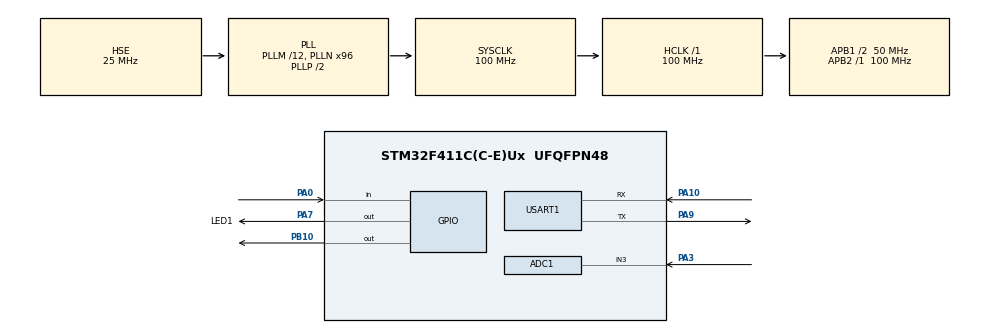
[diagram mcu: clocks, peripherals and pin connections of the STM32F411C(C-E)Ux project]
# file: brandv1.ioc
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ADC1.Channel-0\#ChannelRegularConversion=ADC_CHANNEL_3
ADC1.NbrOfConversionFlag=1
ADC1.Rank-0\#ChannelRegularConversion=1
ADC1.SamplingTime-0\#ChannelRegularConversion=ADC_SAMPLETIME_3CYCLES
ADC1.master=1
Mcu.Family=STM32F4
Mcu.Name=STM32F411C(C-E)Ux
Mcu.Package=UFQFPN48
NVIC.PriorityGroup=NVIC_PRIORITYGROUP_2
NVIC.TIM1_BRK_TIM9_IRQn=true\:2\:0\:true\:false\:true\:true\:true\:true
NVIC.USART1_IRQn=true\:2\:2\:true\:false\:true\:true\:true\:true
PA0-WKUP.GPIO_PuPd=GPIO_NOPULL
PA0-WKUP.Signal=GPIO_Input
PA10.Mode=Asynchronous
PA10.Signal=USART1_RX
PA13.Mode=Serial_Wire
PA13.Signal=SYS_JTMS-SWDIO
PA14.Mode=Serial_Wire
PA14.Signal=SYS_JTCK-SWCLK
PA3.Signal=ADCx_IN3
PA7.GPIO_Label=LED1
PA7.PinState=GPIO_PIN_SET
PA7.Signal=GPIO_Output
PA9.Mode=Asynchronous
PA9.Signal=USART1_TX
PB10.Signal=GPIO_Output
PC14-OSC32_IN.Mode=LSE-External-Oscillator
PC14-OSC32_IN.Signal=RCC_OSC32_IN
PC15-OSC32_OUT.Mode=LSE-External-Oscillator
PC15-OSC32_OUT.Signal=RCC_OSC32_OUT
PH0\ -\ OSC_IN.Mode=HSE-External-Oscillator
PH0\ -\ OSC_IN.Signal=RCC_OSC_IN
PH1\ -\ OSC_OUT.Mode=HSE-External-Oscillator
PH1\ -\ OSC_OUT.Signal=RCC_OSC_OUT
ProjectManager.HeapSize=0x200
ProjectManager.StackSize=0x400
ProjectManager.TargetToolchain=MDK-ARM V5.32
RCC.48MHZClocksFreq_Value=50000000
RCC.AHBFreq_Value=100000000
RCC.APB1CLKDivider=RCC_HCLK_DIV2
RCC.APB1Freq_Value=50000000
RCC.APB1TimFreq_Value=100000000
RCC.APB2Freq_Value=100000000
RCC.APB2TimFreq_Value=100000000
RCC.CortexFreq_Value=100000000
RCC.HCLKFreq_Value=100000000
RCC.HSE_VALUE=25000000
RCC.HSI_VALUE=16000000
RCC.PLLM=12
RCC.PLLN=96
RCC.PLLSourceVirtual=RCC_PLLSOURCE_HSE
RCC.SYSCLKFreq_VALUE=100000000
RCC.SYSCLKSource=RCC_SYSCLKSOURCE_PLLCLK
RCC.VCOOutputFreq_Value=200000000
SH.ADCx_IN3.0=ADC1_IN3,IN3
TIM11.AutoReloadPreload=TIM_AUTORELOAD_PRELOAD_ENABLE
TIM11.Prescaler=1000
TIM9.Period=1000-1
TIM9.Prescaler=100-1
USART1.VirtualMode=VM_ASYNC
VP_TIM11_VS_ClockSourceINT.Mode=Enable_Timer
VP_TIM11_VS_OPM.Mode=OPM_bit
VP_TIM9_VS_ClockSourceINT.Mode=Internal
board=custom

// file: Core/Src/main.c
/* USER CODE BEGIN Header */
/**
  ******************************************************************************
  * @file           : main.c
  * @brief          : Main program body
  ******************************************************************************
  * @attention
  *
  * Copyright (c) 2025 STMicroelectronics.
  * All rights reserved.
  *
  * This software is licensed under terms that can be found in the LICENSE file
  * in the root directory of this software component.
  * If no LICENSE file comes with this software, it is provided AS-IS.
  *
  ******************************************************************************
  */
/* USER CODE END Header */
#include "main.h"
#include "adc.h"
#include "tim.h"
#include "usart.h"
#include "gpio.h"

void SystemClock_Config(void);

int main(void)
{

  /* MCU Configuration--------------------------------------------------------*/

  /* Reset of all peripherals, Initializes the Flash interface and the Systick. */
  HAL_Init();

  /* Configure the system clock */
  SystemClock_Config();

  /* Initialize all configured peripherals */
  MX_GPIO_Init();
  MX_USART1_UART_Init();
  MX_TIM9_Init();
  MX_TIM11_Init();
  MX_ADC1_Init();
  /* USER CODE BEGIN 2 */

  UART_SendString("Enter\r\n");

  /* USER CODE END 2 */

  /* Infinite loop */
  /* USER CODE BEGIN WHILE */
  while (1)
  {

 Key_Event_t event = Get_Key_Event(); // 获取按键事件

    if (event != KEY_EVENT_NONE) // 如果有新事件发生
    {
        switch (event)
        {
            case KEY_EVENT_UP_PRESS:    printf("摇杆: 上\r\n"); break;
            case KEY_EVENT_DOWN_PRESS:  printf("摇杆: 下\r\n"); break;
            case KEY_EVENT_LEFT_PRESS:  printf("摇杆: 左\r\n"); break;
            case KEY_EVENT_RIGHT_PRESS: printf("摇杆: 右\r\n"); break;

            case KEY_EVENT_OK_CLICK:    printf("OK键: 单击\r\n"); break;
            case KEY_EVENT_OK_DOUBLE:   printf("OK键: 双击\r\n"); break;
            case KEY_EVENT_OK_LONG:     printf("OK键: 长按\r\n"); break;

            default: break;
        }
    }
    /* USER CODE END WHILE */

  }
}

void SystemClock_Config(void)
{
  RCC_OscInitTypeDef RCC_OscInitStruct = {0};
  RCC_ClkInitTypeDef RCC_ClkInitStruct = {0};

  /** Configure the main internal regulator output voltage
  */
  __HAL_RCC_PWR_CLK_ENABLE();
  __HAL_PWR_VOLTAGESCALING_CONFIG(PWR_REGULATOR_VOLTAGE_SCALE1);

  /** Initializes the RCC Oscillators according to the specified parameters
  * in the RCC_OscInitTypeDef structure.
  */
  RCC_OscInitStruct.OscillatorType = RCC_OSCILLATORTYPE_HSE;
  RCC_OscInitStruct.HSEState = RCC_HSE_ON;
  RCC_OscInitStruct.PLL.PLLState = RCC_PLL_ON;
  RCC_OscInitStruct.PLL.PLLSource = RCC_PLLSOURCE_HSE;
  RCC_OscInitStruct.PLL.PLLM = 12;
  RCC_OscInitStruct.PLL.PLLN = 96;
  RCC_OscInitStruct.PLL.PLLP = RCC_PLLP_DIV2;
  RCC_OscInitStruct.PLL.PLLQ = 4;
  if (HAL_RCC_OscConfig(&RCC_OscInitStruct) != HAL_OK)
  {
    Error_Handler();
  }

  /** Initializes the CPU, AHB and APB buses clocks
  */
  RCC_ClkInitStruct.ClockType = RCC_CLOCKTYPE_HCLK|RCC_CLOCKTYPE_SYSCLK
                              |RCC_CLOCKTYPE_PCLK1|RCC_CLOCKTYPE_PCLK2;
  RCC_ClkInitStruct.SYSCLKSource = RCC_SYSCLKSOURCE_PLLCLK;
  RCC_ClkInitStruct.AHBCLKDivider = RCC_SYSCLK_DIV1;
  RCC_ClkInitStruct.APB1CLKDivider = RCC_HCLK_DIV2;
  RCC_ClkInitStruct.APB2CLKDivider = RCC_HCLK_DIV1;

  if (HAL_RCC_ClockConfig(&RCC_ClkInitStruct, FLASH_LATENCY_3) != HAL_OK)
  {
    Error_Handler();
  }
}

void Error_Handler(void)
{
  __disable_irq();
  while (1)
  {
  }
}
